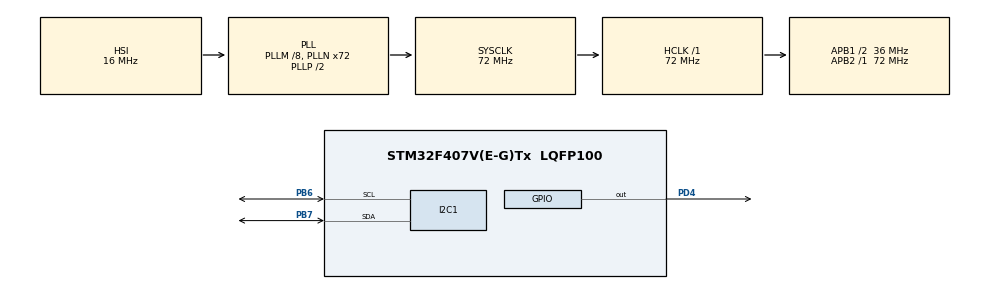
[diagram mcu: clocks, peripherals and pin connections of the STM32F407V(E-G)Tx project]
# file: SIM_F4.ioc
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Mcu.Family=STM32F4
Mcu.Name=STM32F407V(E-G)Tx
Mcu.Package=LQFP100
NVIC.PriorityGroup=NVIC_PRIORITYGROUP_4
PA13.Mode=Serial_Wire
PA13.Signal=SYS_JTMS-SWDIO
PA14.Mode=Serial_Wire
PA14.Signal=SYS_JTCK-SWCLK
PB6.Mode=I2C
PB6.Signal=I2C1_SCL
PB7.Mode=I2C
PB7.Signal=I2C1_SDA
PD4.GPIO_PuPd=GPIO_PULLUP
PD4.PinState=GPIO_PIN_RESET
PD4.Signal=GPIO_Output
PH0-OSC_IN.Mode=HSE-External-Oscillator
PH0-OSC_IN.Signal=RCC_OSC_IN
PH1-OSC_OUT.Mode=HSE-External-Oscillator
PH1-OSC_OUT.Signal=RCC_OSC_OUT
ProjectManager.HeapSize=0x200
ProjectManager.StackSize=0x400
ProjectManager.TargetToolchain=Makefile
RCC.48MHZClocksFreq_Value=36000000
RCC.AHBFreq_Value=72000000
RCC.APB1CLKDivider=RCC_HCLK_DIV2
RCC.APB1Freq_Value=36000000
RCC.APB1TimFreq_Value=72000000
RCC.APB2Freq_Value=72000000
RCC.APB2TimFreq_Value=72000000
RCC.CortexFreq_Value=72000000
RCC.HCLKFreq_Value=72000000
RCC.HSE_VALUE=25000000
RCC.HSI_VALUE=16000000
RCC.LSE_VALUE=32768
RCC.PLLM=8
RCC.PLLN=72
RCC.SYSCLKFreq_VALUE=72000000
RCC.SYSCLKSource=RCC_SYSCLKSOURCE_PLLCLK
RCC.VCOOutputFreq_Value=144000000
board=custom

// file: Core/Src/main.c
/* USER CODE BEGIN Header */
/**
  ******************************************************************************
  * @file           : main.c
  * @brief          : Main program body
  ******************************************************************************
  * @attention
  *
  * Copyright (c) 2024 STMicroelectronics.
  * All rights reserved.
  *
  * This software is licensed under terms that can be found in the LICENSE file
  * in the root directory of this software component.
  * If no LICENSE file comes with this software, it is provided AS-IS.
  *
  ******************************************************************************
  */
/* USER CODE END Header */
#include "main.h"
#include "SHT.h"
#include "bmp280.h"
#define I2C_TIMEOUT_BUSY_FLAG 1000 // Đơn vị: ms

I2C_HandleTypeDef hi2c1;

void SystemClock_Config(void);
static void MX_GPIO_Init(void);
static void MX_I2C1_Init(void);

/* USER CODE BEGIN 0 */
float temperature;
float humidity;
uint8_t diachi;

BMP280_HandleTypedef bmp280;
bmp280_params_t bmp280_params;

float pressure;
float temperature_BMP280;
void I2C_ResetBus(I2C_HandleTypeDef *hi2c)
{
  if (__HAL_I2C_GET_FLAG(hi2c, I2C_FLAG_BUSY))
  {
    HAL_I2C_DeInit(hi2c); // Hủy cấu hình hiện tại của I2C
    HAL_Delay(10);        // Chờ một thời gian để ổn định
    HAL_I2C_Init(hi2c);   // Khởi tạo lại I2C
  }
}

/* USER CODE END 0 */

int main(void)
{

  /* MCU Configuration--------------------------------------------------------*/

  /* Reset of all peripherals, Initializes the Flash interface and the Systick. */
  HAL_Init();

  /* Configure the system clock */
  SystemClock_Config();

  /* Initialize all configured peripherals */
  MX_GPIO_Init();
  MX_I2C1_Init();
  /* USER CODE BEGIN 2 */
  SHT31_Config(SHT31_ADDRESS_A, &hi2c1);
  // Kiểm tra và reset bus I2C nếu có lỗi
  I2C_ResetBus(&hi2c1);

  // Đảm bảo rằng I2C không còn bận trước khi tiếp tục
  while (hi2c1.State != HAL_I2C_STATE_READY)
  {
    // Có thể thêm một delay nhỏ nếu cần thiết
    HAL_Delay(1); // Thử lại sau 1ms
  }

  bmp280.i2c = &hi2c1;                // hi2c1 là biến I2C đã khởi tạo
  bmp280.addr = BMP280_I2C_ADDRESS_0; // hoặc BME280_I2C_ADDRESS_1

  // Khởi tạo các tham số mặc định cho BMP280
  bmp280_init_default_params(&bmp280_params);

  // Khởi tạo BMP280
  if (!bmp280_init(&bmp280, &bmp280_params))
  {
    // Xử lý lỗi khởi tạo
    while (1)
      ;
  }
  /* USER CODE END 2 */

  /* Infinite loop */
  while (1)
  {

    /* USER CODE BEGIN 3 */
    if (SHT31_GetData(SHT31_Periodic, SHT31_Medium, SHT31_NON_Stretch, SHT31_1) == SHT31_OK)
    {
      temperature = SHT31_GetTemperature();
      humidity = SHT31_GetHumidity();
    }
    HAL_Delay(2000);
    bmp280_read_float(&bmp280, &temperature_BMP280, &pressure);

    HAL_GPIO_TogglePin(GPIOD, GPIO_PIN_4);
    HAL_Delay(1000);
  }
  /* USER CODE END 3 */
}

void SystemClock_Config(void)
{
  RCC_OscInitTypeDef RCC_OscInitStruct = {0};
  RCC_ClkInitTypeDef RCC_ClkInitStruct = {0};

  /** Configure the main internal regulator output voltage
  */
  __HAL_RCC_PWR_CLK_ENABLE();
  __HAL_PWR_VOLTAGESCALING_CONFIG(PWR_REGULATOR_VOLTAGE_SCALE1);

  /** Initializes the RCC Oscillators according to the specified parameters
  * in the RCC_OscInitTypeDef structure.
  */
  RCC_OscInitStruct.OscillatorType = RCC_OSCILLATORTYPE_HSI;
  RCC_OscInitStruct.HSIState = RCC_HSI_ON;
  RCC_OscInitStruct.HSICalibrationValue = RCC_HSICALIBRATION_DEFAULT;
  RCC_OscInitStruct.PLL.PLLState = RCC_PLL_ON;
  RCC_OscInitStruct.PLL.PLLSource = RCC_PLLSOURCE_HSI;
  RCC_OscInitStruct.PLL.PLLM = 8;
  RCC_OscInitStruct.PLL.PLLN = 72;
  RCC_OscInitStruct.PLL.PLLP = RCC_PLLP_DIV2;
  RCC_OscInitStruct.PLL.PLLQ = 4;
  if (HAL_RCC_OscConfig(&RCC_OscInitStruct) != HAL_OK)
  {
    Error_Handler();
  }

  /** Initializes the CPU, AHB and APB buses clocks
  */
  RCC_ClkInitStruct.ClockType = RCC_CLOCKTYPE_HCLK|RCC_CLOCKTYPE_SYSCLK
                              |RCC_CLOCKTYPE_PCLK1|RCC_CLOCKTYPE_PCLK2;
  RCC_ClkInitStruct.SYSCLKSource = RCC_SYSCLKSOURCE_PLLCLK;
  RCC_ClkInitStruct.AHBCLKDivider = RCC_SYSCLK_DIV1;
  RCC_ClkInitStruct.APB1CLKDivider = RCC_HCLK_DIV2;
  RCC_ClkInitStruct.APB2CLKDivider = RCC_HCLK_DIV1;

  if (HAL_RCC_ClockConfig(&RCC_ClkInitStruct, FLASH_LATENCY_2) != HAL_OK)
  {
    Error_Handler();
  }
}

static void MX_I2C1_Init(void)
{

  hi2c1.Instance = I2C1;
  hi2c1.Init.ClockSpeed = 400000;
  hi2c1.Init.DutyCycle = I2C_DUTYCYCLE_2;
  hi2c1.Init.OwnAddress1 = 0;
  hi2c1.Init.AddressingMode = I2C_ADDRESSINGMODE_7BIT;
  hi2c1.Init.DualAddressMode = I2C_DUALADDRESS_DISABLE;
  hi2c1.Init.OwnAddress2 = 0;
  hi2c1.Init.GeneralCallMode = I2C_GENERALCALL_DISABLE;
  hi2c1.Init.NoStretchMode = I2C_NOSTRETCH_DISABLE;
  if (HAL_I2C_Init(&hi2c1) != HAL_OK)
  {
    Error_Handler();
  }

}

static void MX_GPIO_Init(void)
{
  GPIO_InitTypeDef GPIO_InitStruct = {0};

  /* GPIO Ports Clock Enable */
  __HAL_RCC_GPIOH_CLK_ENABLE();
  __HAL_RCC_GPIOA_CLK_ENABLE();
  __HAL_RCC_GPIOD_CLK_ENABLE();
  __HAL_RCC_GPIOB_CLK_ENABLE();

  /*Configure GPIO pin Output Level */
  HAL_GPIO_WritePin(GPIOD, GPIO_PIN_4, GPIO_PIN_RESET);

  /*Configure GPIO pin : PD4 */
  GPIO_InitStruct.Pin = GPIO_PIN_4;
  GPIO_InitStruct.Mode = GPIO_MODE_OUTPUT_PP;
  GPIO_InitStruct.Pull = GPIO_PULLUP;
  GPIO_InitStruct.Speed = GPIO_SPEED_FREQ_LOW;
  HAL_GPIO_Init(GPIOD, &GPIO_InitStruct);

}

void Error_Handler(void)
{
  __disable_irq();
  while (1)
  {
  }
}
